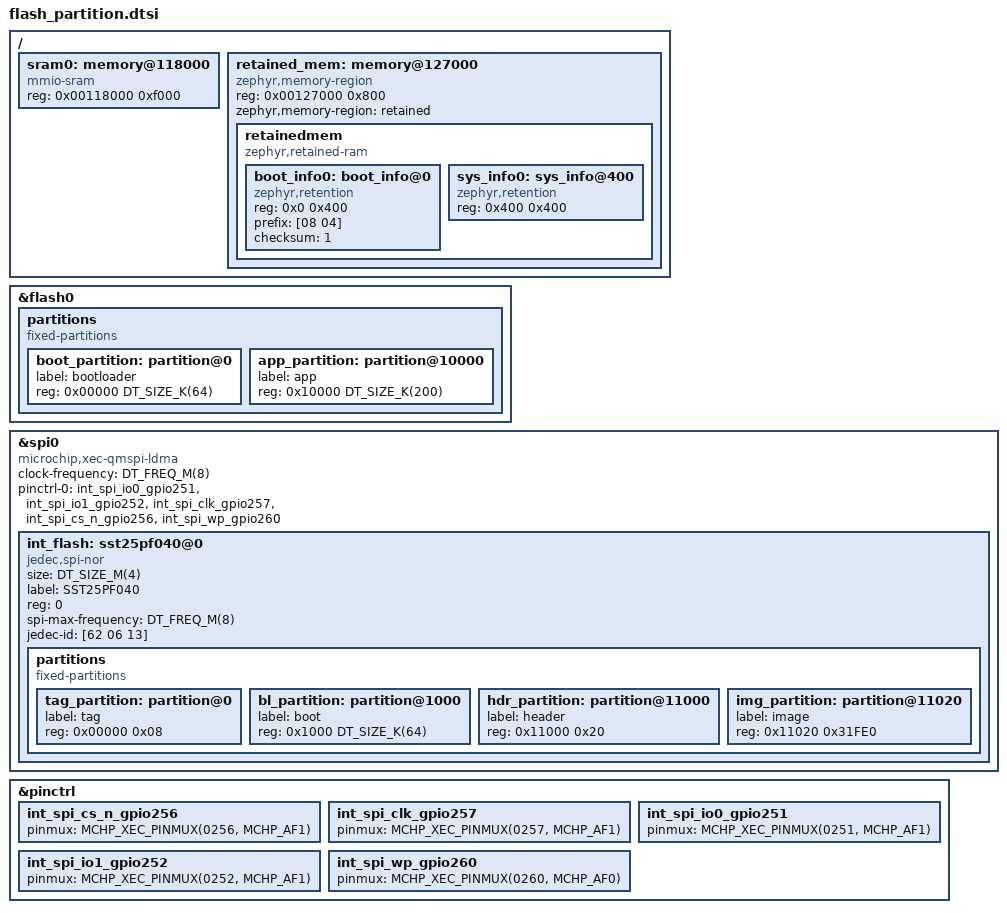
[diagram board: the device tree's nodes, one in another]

/ {
	// /delete-node/ flash@c0000;
	/delete-node/ memory@118000;
	// flash0: flash@b0000 {
	// 	reg = <0x000b0000 0x68000>;
	// };

	sram0: memory@118000 {
		compatible = "mmio-sram";
		// reg = <0x00118000 0xf800>;
		reg = <0x00118000 0xf000>;
	};

    retained_mem: memory@127000 {
		compatible = "zephyr,memory-region", "mmio-sram";
		reg = <0x00127000 0x800>;
		zephyr,memory-region = "retained";
		status = "okay";

		retainedmem {
			compatible = "zephyr,retained-ram";
			status = "okay";
			#address-cells = <1>;
			#size-cells = <1>;

			boot_info0: boot_info@0 {
				compatible = "zephyr,retention";
				status = "okay";
				reg = <0x0 0x400>;

                prefix = [08 04];
				checksum = <1>;
			};

			sys_info0: sys_info@400 {
				compatible = "zephyr,retention";
				status = "okay";
				reg = <0x400 0x400>;
			};
		};
	};
};

&flash0 {
    partitions {
        compatible = "fixed-partitions";
        #address-cells = <1>;
        #size-cells = <1>;

        boot_partition: partition@0 {
            label = "bootloader";
            reg = <0x00000 DT_SIZE_K(64)>;
        };
        app_partition: partition@10000 {
            label = "app";
            // reg = <0x10000 0x58000>;
            reg = <0x10000 DT_SIZE_K(200)>;
        };
    };
};

&spi0 {
    compatible = "microchip,xec-qmspi-ldma";
    status = "okay";
    // port-sel = <1>;
    clock-frequency = <DT_FREQ_M(8)>;

    // // For external flash
    // chip-select = < 0x0 >;
    // pinctrl-0 = < &shd_io0_gpio223 
    //               &shd_io1_gpio224
    //               &shd_clk_gpio056
    //               &shd_cs0_n_gpio055 >;
    // gd25lb256: gd25lb256@0 {
	// 	compatible = "jedec,spi-nor";
	// 	size = <DT_SIZE_M(32)>;
	// 	reg = <0>;
	// 	spi-max-frequency = <DT_FREQ_M(8)>;
	// 	jedec-id = [c8 67 19];
	// 	status = "okay";
	// };

    // For internal flash
    pinctrl-0 = < &int_spi_io0_gpio251 
                  &int_spi_io1_gpio252
                  &int_spi_clk_gpio257
                  &int_spi_cs_n_gpio256
                  &int_spi_wp_gpio260 >;
    int_flash: sst25pf040@0 {
        compatible ="jedec,spi-nor";
        size = <DT_SIZE_M(4)>; // 4M bits (512K Bytes)
        label = "SST25PF040";
        reg = <0>;
        spi-max-frequency = <DT_FREQ_M(8)>; // DT_FREQ_M(40)
        status = "okay";
        jedec-id = [62 06 13];
    };

    pinctrl-names = "default";
};

&int_flash {
    partitions {
        compatible = "fixed-partitions";
        #address-cells = <1>;
        #size-cells = <1>;

        tag_partition: partition@0 {
            label = "tag";
            reg = <0x00000 0x08>;
        };

        bl_partition: partition@1000 {
            label = "boot";
            reg = <0x1000 DT_SIZE_K(64)>;
        };

        hdr_partition: partition@11000 {
            label = "header";
            reg = <0x11000 0x20>;
        };

        img_partition: partition@11020 {
            label = "image";
            // reg = <0x11020 0x58000>;
            reg = <0x11020 0x31FE0>; // 200KB - 20B
        };
    };
};

// &shd_cs0_n_gpio055 {
// 	drive-open-drain;
// 	output-high;
// };

&pinctrl{
    /* Internal flash */
    /omit-if-no-ref/ int_spi_cs_n_gpio256: int_spi_cs_n_gpio256 {
        pinmux = < MCHP_XEC_PINMUX(0256, MCHP_AF1) >;
    };

    /omit-if-no-ref/ int_spi_clk_gpio257: int_spi_clk_gpio257 {
        pinmux = < MCHP_XEC_PINMUX(0257, MCHP_AF1) >;
    };

    /omit-if-no-ref/ int_spi_io0_gpio251: int_spi_io0_gpio251 {
        pinmux = < MCHP_XEC_PINMUX(0251, MCHP_AF1) >;
    };

    /omit-if-no-ref/ int_spi_io1_gpio252: int_spi_io1_gpio252 {
        pinmux = < MCHP_XEC_PINMUX(0252, MCHP_AF1) >;
    };

    /omit-if-no-ref/ int_spi_wp_gpio260: int_spi_wp_gpio260 {
        pinmux = < MCHP_XEC_PINMUX(0260, MCHP_AF0) >;
    };
};
